# DSS_CTRL register map
Vendor: Texas Instruments
Registers are 32-bit, read-write, no defined reset value unless marked. A register's access mark holds for its fields unless they carry their own. Offsets are as the file gives them; [hi:lo] are bit positions; {n}, {i} and the like mark numbered series.

## DSS_CTRL (part 2 of 2)
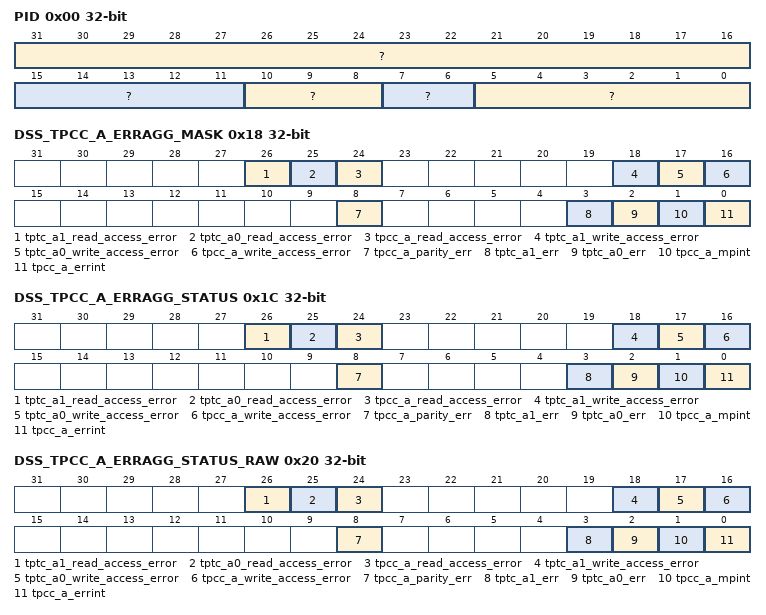
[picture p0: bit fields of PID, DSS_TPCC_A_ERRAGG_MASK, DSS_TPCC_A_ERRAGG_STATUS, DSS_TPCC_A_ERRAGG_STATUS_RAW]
0x00 PID ro
  [31:16] ?, [15:11] ?, [10:8] ?, [7:6] ?, [5:0] ?
0x04 HW_REG0
  [31:0] hwreg0 — Reserved for R&D
0x08 HW_REG1
  [31:0] hwreg1 — Reserved for R&D
0x0C PREVIOUS_NAME
  [31:0] hwreg2 — Reserved for R&D
0x10 HW_REG3
  [31:0] hwreg3 — Reserved for R&D
0x14 DSS_SW_INT
  [3:0] dss_swint — Write pulse bit field: DSS SW Interrupt Write 1 : Generate an interrupt on DSS_SW_INT0
0x18 DSS_TPCC_A_ERRAGG_MASK
  [26] tptc_a1_read_access_error — Mask Interrupt from DSS_TPTC_A1 to aggregated Interrupt DSS_TPCC_A_INTAGG 1 : Interrupt is Masked 0 : Interrupt is Unmasked
  [25] tptc_a0_read_access_error — Mask Interrupt from DSS_TPTC_A0 to aggregated Interrupt DSS_TPCC_A_INTAGG 1 : Interrupt is Masked 0 : Interrupt is Unmasked
  [24] tpcc_a_read_access_error — Mask Interrupt from DSS_TPCC_A to aggregated Interrupt DSS_TPCC_A_INTAGG 1 : Interrupt is Masked 0 : Interrupt is Unmasked
  [18] tptc_a1_write_access_error — Mask Interrupt from DSS_TPTC_A1 to aggregated Interrupt DSS_TPTC_A_INTAGG 1 : Interrupt is Masked 0 : Interrupt is Unmasked
  [17] tptc_a0_write_access_error — Mask Interrupt from DSS_TPTC_A0 to aggregated Interrupt DSS_TPTC_A_INTAGG 1 : Interrupt is Masked 0 : Interrupt is Unmasked
  [16] tpcc_a_write_access_error — Mask Interrupt from DSS_TPCC_A to aggregated Interrupt DSS_TPCC_A_INTAGG 1 : Interrupt is Masked 0 : Interrupt is Unmasked
  [8] tpcc_a_parity_err — Mask Interrupt from DSS_TPCC_A to aggregated Interrupt DSS_TPCC_A_INTAGG 1 : Interrupt is Masked 0 : Interrupt is Unmasked
  [3] tptc_a1_err — Mask Interrupt from DSS_TPTC_A1 to aggregated Interrupt DSS_TPCC_A_INTAGG 1 : Interrupt is Masked 0 : Interrupt is Unmasked
  [2] tptc_a0_err — Mask Interrupt from DSS_TPTC_A0 to aggregated Interrupt DSS_TPCC_A_INTAGG 1 : Interrupt is Masked 0 : Interrupt is Unmasked
  [1] tpcc_a_mpint — Mask Interrupt from DSS_TPCC_A to aggregated Interrupt DSS_TPCC_A_INTAGG 1 : Interrupt is Masked 0 : Interrupt is Unmasked
  [0] tpcc_a_errint — Mask Interrupt from DSS_TPCC_A to aggregated Interrupt DSS_TPCC_A_INTAGG 1 : Interrupt is Masked 0 : Interrupt is Unmasked
0x1C DSS_TPCC_A_ERRAGG_STATUS
  [26] tptc_a1_read_access_error — Rising Edge Capture reg (write 1 to clear): Status of Interrupt from DSS_TPTC_A1. Set only if Interupt is unmasked in DSS_TPCC_A_INTAGG_MASK Wrie 0x1 to clear this interrupt.
  [25] tptc_a0_read_access_error — Rising Edge Capture reg (write 1 to clear): Status of Interrupt from DSS_TPTC_A0. Set only if Interupt is unmasked in DSS_TPCC_A_INTAGG_MASK Wrie 0x1 to clear this interrupt.
  [24] tpcc_a_read_access_error — Rising Edge Capture reg (write 1 to clear): Status of Interrupt from DSS_TPCC_A. Set only if Interupt is unmasked in DSS_TPCC_A_INTAGG_MASK Wrie 0x1 to clear this interrupt.
  [18] tptc_a1_write_access_error — Rising Edge Capture reg (write 1 to clear): Status of Interrupt from DSS_TPTC_A1. Set only if Interupt is unmasked in DSS_TPTC_A_INTAGG_MASK Wrie 0x1 to clear this interrupt.
  [17] tptc_a0_write_access_error — Rising Edge Capture reg (write 1 to clear): Status of Interrupt from DSS_TPTC_A0. Set only if Interupt is unmasked in DSS_TPTC_A_INTAGG_MASK Wrie 0x1 to clear this interrupt.
  [16] tpcc_a_write_access_error — Rising Edge Capture reg (write 1 to clear): Status of Interrupt from DSS_TPCC_A. Set only if Interupt is unmasked in DSS_TPCC_A_INTAGG_MASK Wrie 0x1 to clear this interrupt.
  [8] tpcc_a_parity_err — Rising Edge Capture reg (write 1 to clear): Status of Interrupt from DSS_TPCC_A. Set only if Interupt is unmasked in DSS_TPCC_A_INTAGG_MASK Wrie 0x1 to clear this interrupt.
  [3] tptc_a1_err — Rising Edge Capture reg (write 1 to clear): Status of Interrupt from DSS_TPTC_A1. Set only if Interupt is unmasked in DSS_TPCC_A_INTAGG_MASK Wrie 0x1 to clear this interrupt.
  [2] tptc_a0_err — Rising Edge Capture reg (write 1 to clear): Status of Interrupt from DSS_TPTC_A0. Set only if Interupt is unmasked in DSS_TPCC_A_INTAGG_MASK Wrie 0x1 to clear this interrupt.
  [1] tpcc_a_mpint — Rising Edge Capture reg (write 1 to clear): Status of Interrupt from DSS_TPCC_A. Set only if Interupt is unmasked in DSS_TPCC_A_INTAGG_MASK Wrie 0x1 to clear this interrupt.
  [0] tpcc_a_errint — Rising Edge Capture reg (write 1 to clear): Status of Interrupt from DSS_TPCC_A. Set only if Interupt is unmasked in DSS_TPCC_A_INTAGG_MASK Wrie 0x1 to clear this interrupt.
0x20 DSS_TPCC_A_ERRAGG_STATUS_RAW
  [26] tptc_a1_read_access_error — Rising Edge Capture reg (write 1 to clear): Raw Status of Interrupt from DSS_TPTC_A1. Set irrespective if the Interupt is masked or unmasked in DSS_TPCC_C_INTAGG_MASK
  [25] tptc_a0_read_access_error — Rising Edge Capture reg (write 1 to clear): Raw Status of Interrupt from DSS_TPTC_A0. Set irrespective if the Interupt is masked or unmasked in DSS_TPCC_C_INTAGG_MASK
  [24] tpcc_a_read_access_error — Rising Edge Capture reg (write 1 to clear): Raw Status of Interrupt from DSS_TPCC_A. Set irrespective if the Interupt is masked or unmasked in DSS_TPCC_C_INTAGG_MASK
  [18] tptc_a1_write_access_error — Rising Edge Capture reg (write 1 to clear): Raw Status of Interrupt from DSS_TPTC_A1. Set irrespective if the Interupt is masked or unmasked in DSS_TPTC_A_INTAGG_MASK
  [17] tptc_a0_write_access_error — Rising Edge Capture reg (write 1 to clear): Raw Status of Interrupt from DSS_TPTC_A0. Set irrespective if the Interupt is masked or unmasked in DSS_TPTC_A_INTAGG_MASK
  [16] tpcc_a_write_access_error — Rising Edge Capture reg (write 1 to clear): Raw Status of Interrupt from DSS_TPCC_A. Set irrespective if the Interupt is masked or unmasked in DSS_TPCC_C_INTAGG_MASK
  [8] tpcc_a_parity_err — Rising Edge Capture reg (write 1 to clear): Raw Status of Interrupt from DSS_TPCC_A. Set irrespective if the Interupt is masked or unmasked in DSS_TPCC_C_INTAGG_MASK
  [3] tptc_a1_err — Rising Edge Capture reg (write 1 to clear): Raw Status of Interrupt from DSS_TPTC_A1. Set irrespective if the Interupt is masked or unmasked in DSS_TPCC_C_INTAGG_MASK
  [2] tptc_a0_err — Rising Edge Capture reg (write 1 to clear): Raw Status of Interrupt from DSS_TPTC_A0. Set irrespective if the Interupt is masked or unmasked in DSS_TPCC_C_INTAGG_MASK
  [1] tpcc_a_mpint — Rising Edge Capture reg (write 1 to clear): Raw Status of Interrupt from DSS_TPCC_A. Set irrespective if the Interupt is masked or unmasked in DSS_TPCC_C_INTAGG_MASK
  [0] tpcc_a_errint — Rising Edge Capture reg (write 1 to clear): Raw Status of Interrupt from DSS_TPCC_A. Set irrespective if the Interupt is masked or unmasked in DSS_TPCC_C_INTAGG_MASK
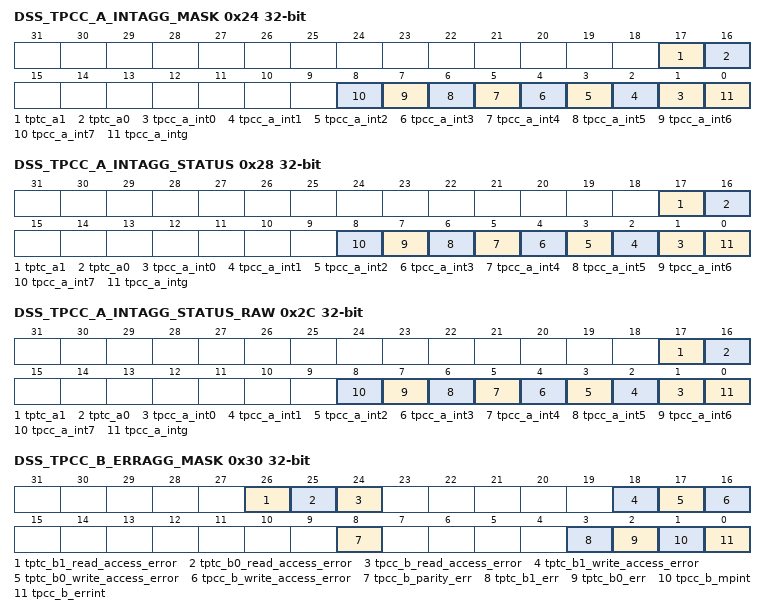
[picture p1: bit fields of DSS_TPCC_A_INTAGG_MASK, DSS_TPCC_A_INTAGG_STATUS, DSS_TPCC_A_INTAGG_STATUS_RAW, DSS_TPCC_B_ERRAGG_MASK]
0x24 DSS_TPCC_A_INTAGG_MASK
  [17] tptc_a1 — Mask Interrupt from DSS_TPTC_A1 to aggregated Interrupt DSS_TPCC_A_INTAGG 1 : Interrupt is Masked 0 : Interrupt is Unmasked
  [16] tptc_a0 — Mask Interrupt from DSS_TPTC_A0 to aggregated Interrupt DSS_TPCC_A_INTAGG 1 : Interrupt is Masked 0 : Interrupt is Unmasked
  [n+1] tpcc_a_int{n} (n=0..7) — Mask Interrupt from DSS_TPCC_A to aggregated Interrupt DSS_TPCC_A_INTAGG 1 : Interrupt is Masked 0 : Interrupt is Unmasked
  [0] tpcc_a_intg — Mask Interrupt from DSS_TPCC_A to aggregated Interrupt DSS_TPCC_A_INTAGG 1 : Interrupt is Masked 0 : Interrupt is Unmasked
0x28 DSS_TPCC_A_INTAGG_STATUS
  [17] tptc_a1 — Rising Edge Capture reg (write 1 to clear): Status of Interrupt from DSS_TPTC_A1. Set only if Interupt is unmasked in DSS_TPCC_A_INTAGG_MASK Wrie 0x1 to clear this interrupt.
  [16] tptc_a0 — Rising Edge Capture reg (write 1 to clear): Status of Interrupt from DSS_TPTC_A0. Set only if Interupt is unmasked in DSS_TPCC_A_INTAGG_MASK Wrie 0x1 to clear this interrupt.
  [n+1] tpcc_a_int{n} (n=0..7) — Rising Edge Capture reg (write 1 to clear): Status of Interrupt from DSS_TPCC_A. Set only if Interupt is unmasked in DSS_TPCC_A_INTAGG_MASK Wrie 0x1 to clear this interrupt.
  [0] tpcc_a_intg — Rising Edge Capture reg (write 1 to clear): Status of Interrupt from DSS_TPCC_A. Set only if Interupt is unmasked in DSS_TPCC_A_INTAGG_MASK Wrie 0x1 to clear this interrupt.
0x2C DSS_TPCC_A_INTAGG_STATUS_RAW
  [17] tptc_a1 — Rising Edge Capture reg (write 1 to clear): Raw Status of Interrupt from DSS_TPTC_A1. Set irrespective if the Interupt is masked or unmasked in DSS_TPCC_A_INTAGG_MASK
  [16] tptc_a0 — Rising Edge Capture reg (write 1 to clear): Raw Status of Interrupt from DSS_TPTC_A0. Set irrespective if the Interupt is masked or unmasked in DSS_TPCC_A_INTAGG_MASK
  [n+1] tpcc_a_int{n} (n=0..7) — Rising Edge Capture reg (write 1 to clear): Raw Status of Interrupt from DSS_TPCC_A. Set irrespective if the Interupt is masked or unmasked in DSS_TPCC_A_INTAGG_MASK
  [0] tpcc_a_intg — Rising Edge Capture reg (write 1 to clear): Raw Status of Interrupt from DSS_TPCC_A. Set irrespective if the Interupt is masked or unmasked in DSS_TPCC_A_INTAGG_MASK
0x30 DSS_TPCC_B_ERRAGG_MASK
  [26] tptc_b1_read_access_error — Mask Error from DSS_TPTC_B1 to aggregated Error DSS_TPCC_B_ERRAGG 1 : Error is Masked 0 : Error is Unmasked
  [25] tptc_b0_read_access_error — Mask Error from DSS_TPTC_B0 to aggregated Error DSS_TPCC_B_ERRAGG 1 : Error is Masked 0 : Error is Unmasked
  [24] tpcc_b_read_access_error — Mask Error from DSS_TPCC_B to aggregated Error DSS_TPCC_B_ERRAGG 1 : Error is Masked 0 : Error is Unmasked
  [18] tptc_b1_write_access_error — Mask Error from DSS_TPTC_B1 to aggregated Error DSS_TPCC_B_ERRAGG 1 : Error is Masked 0 : Error is Unmasked
  [17] tptc_b0_write_access_error — Mask Error from DSS_TPTC_B0 to aggregated Error DSS_TPCC_B_ERRAGG 1 : Error is Masked 0 : Error is Unmasked
  [16] tpcc_b_write_access_error — Mask Error from DSS_TPCC_B to aggregated Error DSS_TPCC_B_ERRAGG 1 : Error is Masked 0 : Error is Unmasked
  [8] tpcc_b_parity_err — Mask Error from DSS_TPCC_B to aggregated Error DSS_TPCC_B_ERRAGG 1 : Error is Masked 0 : Error is Unmasked
  [3] tptc_b1_err — Mask Error from DSS_TPTC_B1 to aggregated Error DSS_TPCC_B_ERRAGG 1 : Error is Masked 0 : Error is Unmasked
  [2] tptc_b0_err — Mask Error from DSS_TPTC_B0 to aggregated Error DSS_TPCC_B_ERRAGG 1 : Error is Masked 0 : Error is Unmasked
  [1] tpcc_b_mpint — Mask Error from DSS_TPCC_B to aggregated Error DSS_TPCC_B_ERRAGG 1 : Error is Masked 0 : Error is Unmasked
  [0] tpcc_b_errint — Mask Error from DSS_TPCC_B to aggregated Error DSS_TPCC_B_ERRAGG 1 : Error is Masked 0 : Error is Unmasked
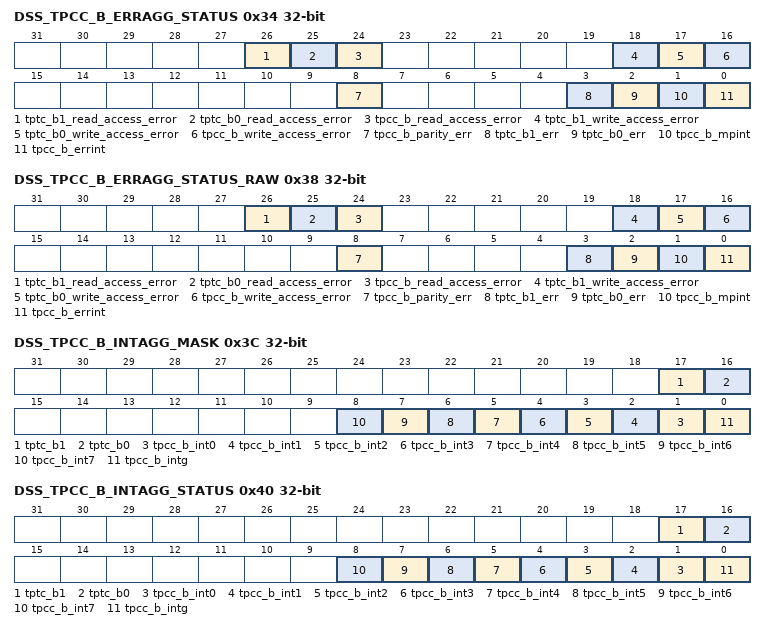
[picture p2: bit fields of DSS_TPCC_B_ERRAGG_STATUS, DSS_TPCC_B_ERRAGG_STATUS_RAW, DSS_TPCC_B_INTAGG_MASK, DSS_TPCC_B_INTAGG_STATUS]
0x34 DSS_TPCC_B_ERRAGG_STATUS
  [26] tptc_b1_read_access_error — Rising Edge Capture reg (write 1 to clear): Status of Error from DSS_TPTC_B1. Set only if Interupt is unmasked in DSS_TPCC_B_ERRAGG_MASK Wrie 0x1 to clear this Error.
  [25] tptc_b0_read_access_error — Rising Edge Capture reg (write 1 to clear): Status of Error from DSS_TPTC_B0. Set only if Interupt is unmasked in DSS_TPCC_B_ERRAGG_MASK Wrie 0x1 to clear this Error.
  [24] tpcc_b_read_access_error — Rising Edge Capture reg (write 1 to clear): Status of Error from DSS_TPCC_B. Set only if Interupt is unmasked in DSS_TPCC_B_ERRAGG_MASK Wrie 0x1 to clear this Error.
  [18] tptc_b1_write_access_error — Rising Edge Capture reg (write 1 to clear): Status of Error from DSS_TPTC_B1. Set only if Interupt is unmasked in DSS_TPCC_B_ERRAGG_MASK Wrie 0x1 to clear this Error.
  [17] tptc_b0_write_access_error — Rising Edge Capture reg (write 1 to clear): Status of Error from DSS_TPTC_B0. Set only if Interupt is unmasked in DSS_TPCC_B_ERRAGG_MASK Wrie 0x1 to clear this Error.
  [16] tpcc_b_write_access_error — Rising Edge Capture reg (write 1 to clear): Status of Error from DSS_TPCC_B. Set only if Interupt is unmasked in DSS_TPCC_B_ERRAGG_MASK Wrie 0x1 to clear this Error.
  [8] tpcc_b_parity_err — Rising Edge Capture reg (write 1 to clear): Status of Error from DSS_TPCC_B. Set only if Interupt is unmasked in DSS_TPCC_B_ERRAGG_MASK Wrie 0x1 to clear this Error.
  [3] tptc_b1_err — Rising Edge Capture reg (write 1 to clear): Status of Error from DSS_TPCC_B1. Set only if Interupt is unmasked in DSS_TPCC_B_ERRAGG_MASK Wrie 0x1 to clear this Error.
  [2] tptc_b0_err — Rising Edge Capture reg (write 1 to clear): Status of Error from DSS_TPTC_B0. Set only if Interupt is unmasked in DSS_TPCC_B_ERRAGG_MASK Wrie 0x1 to clear this Error.
  [1] tpcc_b_mpint — Rising Edge Capture reg (write 1 to clear): Status of Error from DSS_TPCC_B. Set only if Interupt is unmasked in DSS_TPCC_B_ERRAGG_MASK Wrie 0x1 to clear this Error.
  [0] tpcc_b_errint — Rising Edge Capture reg (write 1 to clear): Status of Error from DSS_TPCC_B. Set only if Interupt is unmasked in DSS_TPCC_B_ERRAGG_MASK Wrie 0x1 to clear this Error.
0x38 DSS_TPCC_B_ERRAGG_STATUS_RAW
  [26] tptc_b1_read_access_error — Rising Edge Capture reg (write 1 to clear): Raw Status of Error from DSS_TPTC_B1. Set irrespective if the Interupt is masked or unmasked in DSS_TPCC_B_ERRAGG_MASK
  [25] tptc_b0_read_access_error — Rising Edge Capture reg (write 1 to clear): Raw Status of Error from DSS_TPTC_B0. Set irrespective if the Interupt is masked or unmasked in DSS_TPCC_B_ERRAGG_MASK
  [24] tpcc_b_read_access_error — Rising Edge Capture reg (write 1 to clear): Raw Status of Error from DSS_TPCC_B. Set irrespective if the Interupt is masked or unmasked in DSS_TPCC_B_ERRAGG_MASK
  [18] tptc_b1_write_access_error — Rising Edge Capture reg (write 1 to clear): Raw Status of Error from DSS_TPTC_B1. Set irrespective if the Interupt is masked or unmasked in DSS_TPCC_B_ERRAGG_MASK
  [17] tptc_b0_write_access_error — Rising Edge Capture reg (write 1 to clear): Raw Status of Error from DSS_TPTC_B0. Set irrespective if the Interupt is masked or unmasked in DSS_TPCC_B_ERRAGG_MASK
  [16] tpcc_b_write_access_error — Rising Edge Capture reg (write 1 to clear): Raw Status of Error from DSS_TPCC_B. Set irrespective if the Interupt is masked or unmasked in DSS_TPCC_B_ERRAGG_MASK
  [8] tpcc_b_parity_err — Rising Edge Capture reg (write 1 to clear): Raw Status of Error from DSS_TPCC_B. Set irrespective if the Interupt is masked or unmasked in DSS_TPCC_B_ERRAGG_MASK
  [3] tptc_b1_err — Rising Edge Capture reg (write 1 to clear): Raw Status of Error from DSS_TPCC_B1. Set irrespective if the Interupt is masked or unmasked in DSS_TPCC_B_ERRAGG_MASK
  [2] tptc_b0_err — Rising Edge Capture reg (write 1 to clear): Raw Status of Error from DSS_TPTC_B0. Set irrespective if the Interupt is masked or unmasked in DSS_TPCC_B_ERRAGG_MASK
  [1] tpcc_b_mpint — Rising Edge Capture reg (write 1 to clear): Raw Status of Error from DSS_TPCC_B. Set irrespective if the Interupt is masked or unmasked in DSS_TPCC_B_ERRAGG_MASK
  [0] tpcc_b_errint — Rising Edge Capture reg (write 1 to clear): Raw Status of Error from DSS_TPCC_B. Set irrespective if the Interupt is masked or unmasked in DSS_TPCC_B_ERRAGG_MASK
0x3C DSS_TPCC_B_INTAGG_MASK
  [17] tptc_b1 — Mask Interrupt from DSS_TPTC_B1 to aggregated Interrupt DSS_TPCC_B_INTAGG 1 : Interrupt is Masked 0 : Interrupt is Unmasked
  [16] tptc_b0 — Mask Interrupt from DSS_TPTC_B0 to aggregated Interrupt DSS_TPCC_B_INTAGG 1 : Interrupt is Masked 0 : Interrupt is Unmasked
  [n+1] tpcc_b_int{n} (n=0..7) — Mask Interrupt from DSS_TPCC_B to aggregated Interrupt DSS_TPCC_B_INTAGG 1 : Interrupt is Masked 0 : Interrupt is Unmasked
  [0] tpcc_b_intg — Mask Interrupt from DSS_TPCC_B to aggregated Interrupt DSS_TPCC_B_INTAGG 1 : Interrupt is Masked 0 : Interrupt is Unmasked
0x40 DSS_TPCC_B_INTAGG_STATUS
  [17] tptc_b1 — Rising Edge Capture reg (write 1 to clear): Status of Interrupt from DSS_TPTC_B1. Set only if Interupt is unmasked in DSS_TPCC_B_INTAGG_MASK Wrie 0x1 to clear this interrupt.
  [16] tptc_b0 — Rising Edge Capture reg (write 1 to clear): Status of Interrupt from DSS_TPTC_B0. Set only if Interupt is unmasked in DSS_TPCC_B_INTAGG_MASK Wrie 0x1 to clear this interrupt.
  [n+1] tpcc_b_int{n} (n=0..7) — Rising Edge Capture reg (write 1 to clear): Status of Interrupt from DSS_TPCC_B. Set only if Interupt is unmasked in DSS_TPCC_B_INTAGG_MASK Wrie 0x1 to clear this interrupt.
  [0] tpcc_b_intg — Rising Edge Capture reg (write 1 to clear): Status of Interrupt from DSS_TPCC_B. Set only if Interupt is unmasked in DSS_TPCC_B_INTAGG_MASK Wrie 0x1 to clear this interrupt.
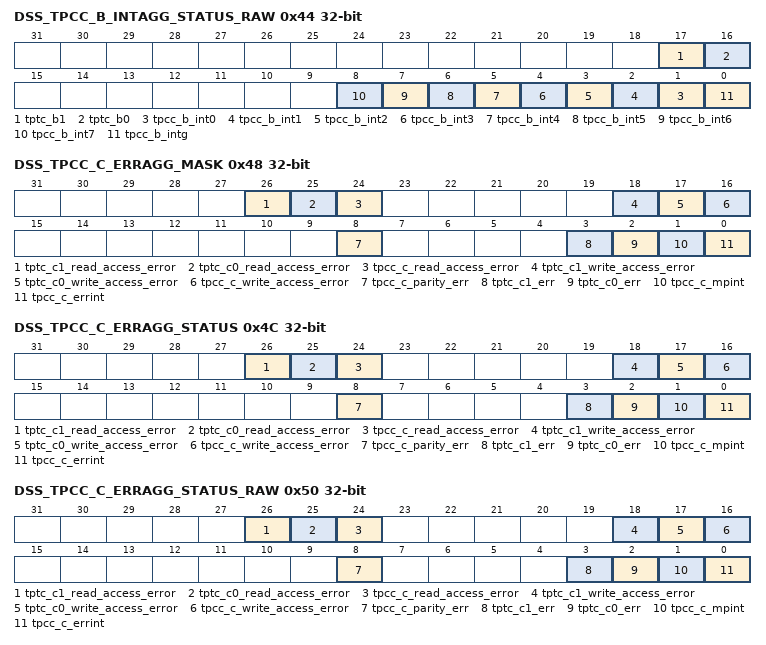
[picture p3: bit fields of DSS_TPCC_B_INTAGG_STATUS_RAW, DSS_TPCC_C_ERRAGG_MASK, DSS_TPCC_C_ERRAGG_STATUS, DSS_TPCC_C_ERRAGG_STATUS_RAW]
0x44 DSS_TPCC_B_INTAGG_STATUS_RAW
  [17] tptc_b1 — Rising Edge Capture reg (write 1 to clear): Raw Status of Interrupt from DSS_TPTC_B1. Set irrespective if the Interupt is masked or unmasked in DSS_TPCC_B_INTAGG_MASK
  [16] tptc_b0 — Rising Edge Capture reg (write 1 to clear): Raw Status of Interrupt from DSS_TPTC_B0. Set irrespective if the Interupt is masked or unmasked in DSS_TPCC_B_INTAGG_MASK
  [n+1] tpcc_b_int{n} (n=0..7) — Rising Edge Capture reg (write 1 to clear): Raw Status of Interrupt from DSS_TPCC_B. Set irrespective if the Interupt is masked or unmasked in DSS_TPCC_B_INTAGG_MASK
  [0] tpcc_b_intg — Rising Edge Capture reg (write 1 to clear): Raw Status of Interrupt from DSS_TPCC_B. Set irrespective if the Interupt is masked or unmasked in DSS_TPCC_B_INTAGG_MASK
0x48 DSS_TPCC_C_ERRAGG_MASK
  [26] tptc_c1_read_access_error — Mask Error from DSS_TPTC_C1 to aggregated Error DSS_TPCC_C_ERRAGG 1 : Error is Masked 0 : Error is Unmasked
  [25] tptc_c0_read_access_error — Mask Error from DSS_TPTC_C0 to aggregated Error DSS_TPCC_C_ERRAGG 1 : Error is Masked 0 : Error is Unmasked
  [24] tpcc_c_read_access_error — Mask Error from DSS_TPCC_C to aggregated Error DSS_TPCC_C_ERRAGG 1 : Error is Masked 0 : Error is Unmasked
  [18] tptc_c1_write_access_error — Mask Error from DSS_TPTC_C1 to aggregated Error DSS_TPCC_C_ERRAGG 1 : Error is Masked 0 : Error is Unmasked
  [17] tptc_c0_write_access_error — Mask Error from DSS_TPTC_C0 to aggregated Error DSS_TPCC_C_ERRAGG 1 : Error is Masked 0 : Error is Unmasked
  [16] tpcc_c_write_access_error — Mask Error from DSS_TPCC_C to aggregated Error DSS_TPCC_C_ERRAGG 1 : Error is Masked 0 : Error is Unmasked
  [8] tpcc_c_parity_err — Mask Error from DSS_TPCC_C to aggregated Error DSS_TPCC_C_ERRAGG 1 : Error is Masked 0 : Error is Unmasked
  [3] tptc_c1_err — Mask Error from DSS_TPTC_C1 to aggregated Error DSS_TPCC_C_ERRAGG 1 : Error is Masked 0 : Error is Unmasked
  [2] tptc_c0_err — Mask Error from DSS_TPTC_C0 to aggregated Error DSS_TPCC_C_ERRAGG 1 : Error is Masked 0 : Error is Unmasked
  [1] tpcc_c_mpint — Mask Error from DSS_TPCC_C to aggregated Error DSS_TPCC_C_ERRAGG 1 : Error is Masked 0 : Error is Unmasked
  [0] tpcc_c_errint — Mask Error from DSS_TPCC_C to aggregated Error DSS_TPCC_C_ERRAGG 1 : Error is Masked 0 : Error is Unmasked
0x4C DSS_TPCC_C_ERRAGG_STATUS
  [26] tptc_c1_read_access_error — Rising Edge Capture reg (write 1 to clear): Status of Error from DSS_TPTC_C1. Set only if Interupt is unmasked in DSS_TPCC_C_ERRAGG_MASK Wrie 0x1 to clear this Error.
  [25] tptc_c0_read_access_error — Rising Edge Capture reg (write 1 to clear): Status of Error from DSS_TPTC_C0. Set only if Interupt is unmasked in DSS_TPCC_C_ERRAGG_MASK Wrie 0x1 to clear this Error.
  [24] tpcc_c_read_access_error — Rising Edge Capture reg (write 1 to clear): Status of Error from DSS_TPCC_C. Set only if Interupt is unmasked in DSS_TPCC_C_ERRAGG_MASK Wrie 0x1 to clear this Error.
  [18] tptc_c1_write_access_error — Rising Edge Capture reg (write 1 to clear): Status of Error from DSS_TPTC_C1. Set only if Interupt is unmasked in DSS_TPCC_C_ERRAGG_MASK Wrie 0x1 to clear this Error.
  [17] tptc_c0_write_access_error — Rising Edge Capture reg (write 1 to clear): Status of Error from DSS_TPTC_C0. Set only if Interupt is unmasked in DSS_TPCC_C_ERRAGG_MASK Wrie 0x1 to clear this Error.
  [16] tpcc_c_write_access_error — Rising Edge Capture reg (write 1 to clear): Status of Error from DSS_TPCC_C. Set only if Interupt is unmasked in DSS_TPCC_C_ERRAGG_MASK Wrie 0x1 to clear this Error.
  [8] tpcc_c_parity_err — Rising Edge Capture reg (write 1 to clear): Status of Error from DSS_TPCC_C. Set only if Interupt is unmasked in DSS_TPCC_C_ERRAGG_MASK Wrie 0x1 to clear this Error.
  [3] tptc_c1_err — Rising Edge Capture reg (write 1 to clear): Status of Error from DSS_TPTC_C1. Set only if Interupt is unmasked in DSS_TPCC_C_ERRAGG_MASK Wrie 0x1 to clear this Error.
  [2] tptc_c0_err — Rising Edge Capture reg (write 1 to clear): Status of Error from DSS_TPTC_C0. Set only if Interupt is unmasked in DSS_TPCC_C_ERRAGG_MASK Wrie 0x1 to clear this Error.
  [1] tpcc_c_mpint — Rising Edge Capture reg (write 1 to clear): Status of Error from DSS_TPCC_C. Set only if Interupt is unmasked in DSS_TPCC_C_ERRAGG_MASK Wrie 0x1 to clear this Error.
  [0] tpcc_c_errint — Rising Edge Capture reg (write 1 to clear): Status of Error from DSS_TPCC_C. Set only if Interupt is unmasked in DSS_TPCC_C_ERRAGG_MASK Wrie 0x1 to clear this Error.
0x50 DSS_TPCC_C_ERRAGG_STATUS_RAW
  [26] tptc_c1_read_access_error — Rising Edge Capture reg (write 1 to clear): Raw Status of Error from DSS_TPTC_C1. Set irrespective if the Interupt is masked or unmasked in DSS_TPCC_C_ERRAGG_MASK
  [25] tptc_c0_read_access_error — Rising Edge Capture reg (write 1 to clear): Raw Status of Error from DSS_TPTC_C0. Set irrespective if the Interupt is masked or unmasked in DSS_TPCC_C_ERRAGG_MASK
  [24] tpcc_c_read_access_error — Rising Edge Capture reg (write 1 to clear): Raw Status of Error from DSS_TPCC_C. Set irrespective if the Interupt is masked or unmasked in DSS_TPCC_C_ERRAGG_MASK
  [18] tptc_c1_write_access_error — Rising Edge Capture reg (write 1 to clear): Raw Status of Error from DSS_TPTC_C1. Set irrespective if the Interupt is masked or unmasked in DSS_TPCC_C_ERRAGG_MASK
  [17] tptc_c0_write_access_error — Rising Edge Capture reg (write 1 to clear): Raw Status of Error from DSS_TPTC_C0. Set irrespective if the Interupt is masked or unmasked in DSS_TPCC_C_ERRAGG_MASK
  [16] tpcc_c_write_access_error — Rising Edge Capture reg (write 1 to clear): Raw Status of Error from DSS_TPCC_C. Set irrespective if the Interupt is masked or unmasked in DSS_TPCC_C_ERRAGG_MASK
  [8] tpcc_c_parity_err — Rising Edge Capture reg (write 1 to clear): Raw Status of Error from DSS_TPCC_C. Set irrespective if the Interupt is masked or unmasked in DSS_TPCC_C_ERRAGG_MASK
  [3] tptc_c1_err — Rising Edge Capture reg (write 1 to clear): Raw Status of Error from DSS_TPTC_C1. Set irrespective if the Interupt is masked or unmasked in DSS_TPCC_C_ERRAGG_MASK
  [2] tptc_c0_err — Rising Edge Capture reg (write 1 to clear): Raw Status of Error from DSS_TPTC_C0. Set irrespective if the Interupt is masked or unmasked in DSS_TPCC_C_ERRAGG_MASK
  [1] tpcc_c_mpint — Rising Edge Capture reg (write 1 to clear): Raw Status of Error from DSS_TPCC_C0. Set irrespective if the Interupt is masked or unmasked in DSS_TPCC_C_ERRAGG_MASK
  [0] tpcc_c_errint — Rising Edge Capture reg (write 1 to clear): Raw Status of Error from DSS_TPCC_C. Set irrespective if the Interupt is masked or unmasked in DSS_TPCC_C_ERRAGG_MASK
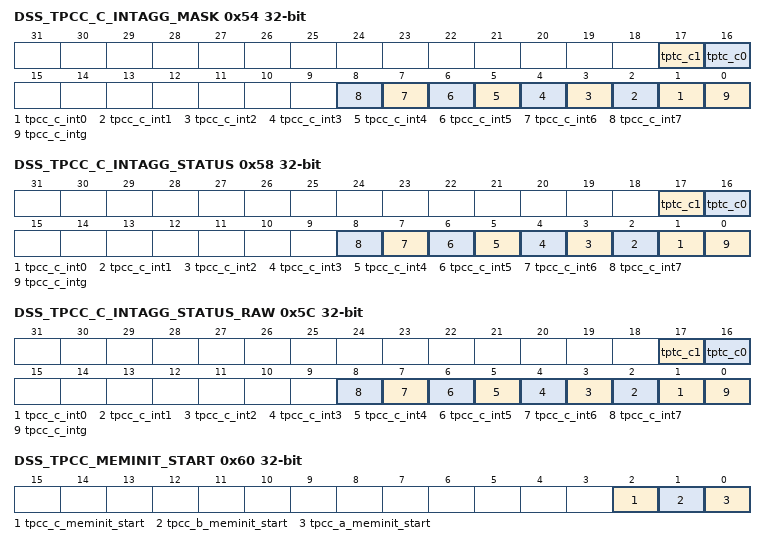
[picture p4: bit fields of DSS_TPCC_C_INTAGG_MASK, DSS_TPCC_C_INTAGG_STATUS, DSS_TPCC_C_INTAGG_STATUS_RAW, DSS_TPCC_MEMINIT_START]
0x54 DSS_TPCC_C_INTAGG_MASK
  [17] tptc_c1 — Mask Interrupt from DSS_TPTC_C1 to aggregated Interrupt DSS_TPCC_C_INTAGG 1 : Interrupt is Masked 0 : Interrupt is Unmasked
  [16] tptc_c0 — Mask Interrupt from DSS_TPTC_C0 to aggregated Interrupt DSS_TPCC_C_INTAGG 1 : Interrupt is Masked 0 : Interrupt is Unmasked
  [n+1] tpcc_c_int{n} (n=0..7) — Mask Interrupt from DSS_TPCC_C to aggregated Interrupt DSS_TPCC_C_INTAGG 1 : Interrupt is Masked 0 : Interrupt is Unmasked
  [0] tpcc_c_intg — Mask Interrupt from DSS_TPCC_C to aggregated Interrupt DSS_TPCC_C_INTAGG 1 : Interrupt is Masked 0 : Interrupt is Unmasked
0x58 DSS_TPCC_C_INTAGG_STATUS
  [17] tptc_c1 — Rising Edge Capture reg (write 1 to clear): Status of Interrupt from DSS_TPTC_C1. Set only if Interupt is unmasked in DSS_TPCC_C_INTAGG_MASK Wrie 0x1 to clear this interrupt.
  [16] tptc_c0 — Rising Edge Capture reg (write 1 to clear): Status of Interrupt from DSS_TPTC_C0. Set only if Interupt is unmasked in DSS_TPCC_C_INTAGG_MASK Wrie 0x1 to clear this interrupt.
  [n+1] tpcc_c_int{n} (n=0..7) — Rising Edge Capture reg (write 1 to clear): Status of Interrupt from DSS_TPCC_C. Set only if Interupt is unmasked in DSS_TPCC_C_INTAGG_MASK Wrie 0x1 to clear this interrupt.
  [0] tpcc_c_intg — Rising Edge Capture reg (write 1 to clear): Status of Interrupt from DSS_TPCC_C. Set only if Interupt is unmasked in DSS_TPCC_C_INTAGG_MASK Wrie 0x1 to clear this interrupt.
0x5C DSS_TPCC_C_INTAGG_STATUS_RAW
  [17] tptc_c1 — Rising Edge Capture reg (write 1 to clear): Raw Status of Interrupt from DSS_TPTC_C1. Set irrespective if the Interupt is masked or unmasked in DSS_TPCC_C_INTAGG_MASK
  [16] tptc_c0 — Rising Edge Capture reg (write 1 to clear): Raw Status of Interrupt from DSS_TPTC_C0. Set irrespective if the Interupt is masked or unmasked in DSS_TPCC_C_INTAGG_MASK
  [n+1] tpcc_c_int{n} (n=0..7) — Rising Edge Capture reg (write 1 to clear): Raw Status of Interrupt from DSS_TPCC_C. Set irrespective if the Interupt is masked or unmasked in DSS_TPCC_C_INTAGG_MASK
  [0] tpcc_c_intg — Rising Edge Capture reg (write 1 to clear): Raw Status of Interrupt from DSS_TPCC_C. Set irrespective if the Interupt is masked or unmasked in DSS_TPCC_C_INTAGG_MASK
0x60 DSS_TPCC_MEMINIT_START
  [2] tpcc_c_meminit_start — Write pulse bit field: Start Memory intialization of TPCC A Param memory. Write 0x1 to start memory initilization. Write 0x0 after ensuring Memory intilization is in progress or has completed. Before starting new initilzation sequence ensure that there is no initilization sequence is in progress (ie TPCC_C_MEMINIT_STATUS should be 0x0) and clear any previouls complettion status(ie write 0x1 to clear TPCC_C_MEMINIT_DONE)
  [1] tpcc_b_meminit_start — Write pulse bit field: Start Memory intialization of TPCC A Param memory. Write 0x1 to start memory initilization. Write 0x0 after ensuring Memory intilization is in progress or has completed. Before starting new initilzation sequence ensure that there is no initilization sequence is in progress (ie TPCC_B_MEMINIT_STATUS should be 0x0) and clear any previouls complettion status(ie write 0x1 to clear TPCC_B_MEMINIT_DONE)
  [0] tpcc_a_meminit_start — Write pulse bit field: Start Memory intialization of TPCC A Param memory. Write 0x1 to start memory initilization. Write 0x0 after ensuring Memory intilization is in progress or has completed. Before starting new initilzation sequence ensure that there is no initilization sequence is in progress (ie TPCC_A_MEMINIT_STATUS should be 0x0) and clear any previouls complettion status(ie write 0x1 to clear TPCC_A_MEMINIT_DONE)
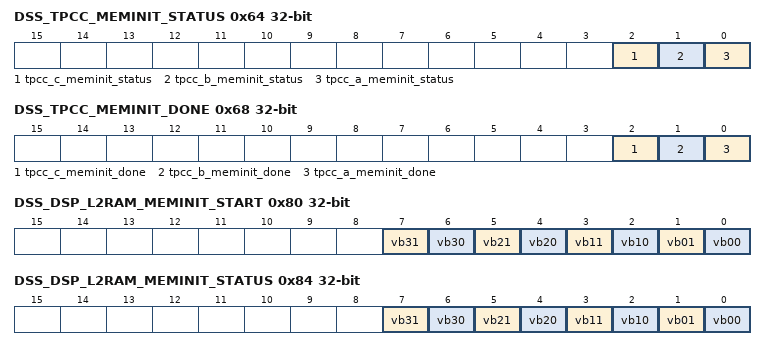
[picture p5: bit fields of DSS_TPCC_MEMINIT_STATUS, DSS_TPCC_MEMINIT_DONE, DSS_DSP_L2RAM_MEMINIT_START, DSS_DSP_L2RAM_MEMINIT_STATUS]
0x64 DSS_TPCC_MEMINIT_STATUS ro
  [2] tpcc_c_meminit_status — Status field. Read value 0x1 indicates previously triggered Memory intialization of TPCC A Param memory is in progress.
  [1] tpcc_b_meminit_status — Status field. Read value 0x1 indicates previously triggered Memory intialization of TPCC A Param memory is in progress.
  [0] tpcc_a_meminit_status — Status field. Read value 0x1 indicates previously triggered Memory intialization of TPCC A Param memory is in progress.
0x68 DSS_TPCC_MEMINIT_DONE
  [2] tpcc_c_meminit_done — Rising Edge Capture reg (write 1 to clear): Status field. Read value 0x1 indicates previously triggered Memory intialization of TPCC A Param memory is complte. Write 0x1 to clear status. Refer TPCC Memory initialization sequnce in EDMA section for more details
  [1] tpcc_b_meminit_done — Rising Edge Capture reg (write 1 to clear): Status field. Read value 0x1 indicates previously triggered Memory intialization of TPCC A Param memory is complte. Write 0x1 to clear status. Refer TPCC Memory initialization sequnce in EDMA section for more details
  [0] tpcc_a_meminit_done — Rising Edge Capture reg (write 1 to clear): Status field. Read value 0x1 indicates previously triggered Memory intialization of TPCC A Param memory is complte. Write 0x1 to clear status. Refer TPCC Memory initialization sequnce in EDMA section for more details
0x80 DSS_DSP_L2RAM_MEMINIT_START
  [7] vb31 — Write pulse bit field: Start Memory intialization of DSP L2 memory. Write 0x1 to start memory initilization. Write 0x0 after ensuring Memory intilization is in progress or has completed. Before starting new initilzation sequence ensure that there is no initilization sequence is in progress (ie DSS_DSP_L2RAM_MEMINIT_STATUS should be 0x0) and clear any previouls complettion status(ie write 0x1 to clear DSS_DSP_L2RAM_MEMINIT_DONE)
  [6] vb30 — Write pulse bit field: Start Memory intialization of DSP L2 memory. Write 0x1 to start memory initilization. Write 0x0 after ensuring Memory intilization is in progress or has completed. Before starting new initilzation sequence ensure that there is no initilization sequence is in progress (ie DSS_DSP_L2RAM_MEMINIT_STATUS should be 0x0) and clear any previouls complettion status(ie write 0x1 to clear DSS_DSP_L2RAM_MEMINIT_DONE)
  [5] vb21 — Write pulse bit field: Start Memory intialization of DSP L2 memory. Write 0x1 to start memory initilization. Write 0x0 after ensuring Memory intilization is in progress or has completed. Before starting new initilzation sequence ensure that there is no initilization sequence is in progress (ie DSS_DSP_L2RAM_MEMINIT_STATUS should be 0x0) and clear any previouls complettion status(ie write 0x1 to clear DSS_DSP_L2RAM_MEMINIT_DONE)
  [4] vb20 — Write pulse bit field: Start Memory intialization of DSP L2 memory. Write 0x1 to start memory initilization. Write 0x0 after ensuring Memory intilization is in progress or has completed. Before starting new initilzation sequence ensure that there is no initilization sequence is in progress (ie DSS_DSP_L2RAM_MEMINIT_STATUS should be 0x0) and clear any previouls complettion status(ie write 0x1 to clear DSS_DSP_L2RAM_MEMINIT_DONE)
  [3] vb11 — Write pulse bit field: Start Memory intialization of DSP L2 memory. Write 0x1 to start memory initilization. Write 0x0 after ensuring Memory intilization is in progress or has completed. Before starting new initilzation sequence ensure that there is no initilization sequence is in progress (ie DSS_DSP_L2RAM_MEMINIT_STATUS should be 0x0) and clear any previouls complettion status(ie write 0x1 to clear DSS_DSP_L2RAM_MEMINIT_DONE)
  [2] vb10 — Write pulse bit field: Start Memory intialization of DSP L2 memory. Write 0x1 to start memory initilization. Write 0x0 after ensuring Memory intilization is in progress or has completed. Before starting new initilzation sequence ensure that there is no initilization sequence is in progress (ie DSS_DSP_L2RAM_MEMINIT_STATUS should be 0x0) and clear any previouls complettion status(ie write 0x1 to clear DSS_DSP_L2RAM_MEMINIT_DONE)
  [1] vb01 — Write pulse bit field: Start Memory intialization of DSP L2 memory. Write 0x1 to start memory initilization. Write 0x0 after ensuring Memory intilization is in progress or has completed. Before starting new initilzation sequence ensure that there is no initilization sequence is in progress (ie DSS_DSP_L2RAM_MEMINIT_STATUS should be 0x0) and clear any previouls complettion status(ie write 0x1 to clear DSS_DSP_L2RAM_MEMINIT_DONE)
  [0] vb00 — Write pulse bit field: Start Memory intialization of DSP L2 memory. Write 0x1 to start memory initilization. Write 0x0 after ensuring Memory intilization is in progress or has completed. Before starting new initilzation sequence ensure that there is no initilization sequence is in progress (ie DSS_DSP_L2RAM_MEMINIT_STATUS should be 0x0) and clear any previouls complettion status(ie write 0x1 to clear DSS_DSP_L2RAM_MEMINIT_DONE)
0x84 DSS_DSP_L2RAM_MEMINIT_STATUS ro
  [7] vb31 — Status field. Read value 0x1 indicates previously triggered Memory intialization of DSP L2 memory is in progress.
  [6] vb30 — Status field. Read value 0x1 indicates previously triggered Memory intialization of DSP L2 memory is in progress.
  [5] vb21 — Status field. Read value 0x1 indicates previously triggered Memory intialization of DSP L2 memory is in progress.
  [4] vb20 — Status field. Read value 0x1 indicates previously triggered Memory intialization of DSP L2 memory is in progress.
  [3] vb11 — Status field. Read value 0x1 indicates previously triggered Memory intialization of DSP L2 memory is in progress.
  [2] vb10 — Status field. Read value 0x1 indicates previously triggered Memory intialization of DSP L2 memory is in progress.
  [1] vb01 — Status field. Read value 0x1 indicates previously triggered Memory intialization of DSP L2 memory is in progress.
  [0] vb00 — Status field. Read value 0x1 indicates previously triggered Memory intialization of DSP L2 memory is in progress.
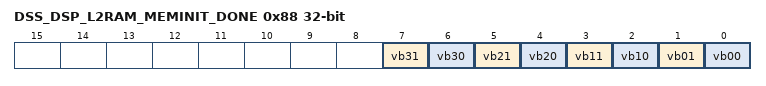
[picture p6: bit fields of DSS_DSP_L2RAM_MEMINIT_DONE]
0x88 DSS_DSP_L2RAM_MEMINIT_DONE
  [7] vb31 — Rising Edge Capture reg (write 1 to clear): Status field. Read value 0x1 indicates previously triggered Memory intialization of L2 Memory is complete. Write 0x1 to clear status.
  [6] vb30 — Rising Edge Capture reg (write 1 to clear): Status field. Read value 0x1 indicates previously triggered Memory intialization of L2 Memory is complete. Write 0x1 to clear status.
  [5] vb21 — Rising Edge Capture reg (write 1 to clear): Status field. Read value 0x1 indicates previously triggered Memory intialization of L2 Memory is complete. Write 0x1 to clear status.
  [4] vb20 — Rising Edge Capture reg (write 1 to clear): Status field. Read value 0x1 indicates previously triggered Memory intialization of L2 Memory is complete. Write 0x1 to clear status.
  [3] vb11 — Rising Edge Capture reg (write 1 to clear): Status field. Read value 0x1 indicates previously triggered Memory intialization of L2 Memory is complete. Write 0x1 to clear status.
  [2] vb10 — Rising Edge Capture reg (write 1 to clear): Status field. Read value 0x1 indicates previously triggered Memory intialization of L2 Memory is complete. Write 0x1 to clear status.
  [1] vb01 — Rising Edge Capture reg (write 1 to clear): Status field. Read value 0x1 indicates previously triggered Memory intialization of L2 Memory is complete. Write 0x1 to clear status.
  [0] vb00 — Rising Edge Capture reg (write 1 to clear): Status field. Read value 0x1 indicates previously triggered Memory intialization of L2 Memory is complete. Write 0x1 to clear status.
